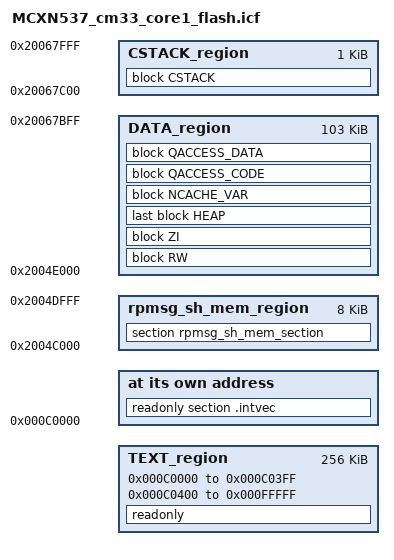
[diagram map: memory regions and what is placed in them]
/*
** ###################################################################
**     Processors:          MCXN537VAB_cm33_core1
**                          MCXN537VDF_cm33_core1
**                          MCXN537VKL_cm33_core1
**                          MCXN537VPB_cm33_core1
**
**     Compiler:            IAR ANSI C/C++ Compiler for ARM
**     Reference manual:    MCXNx4x Reference Manual
**     Version:             rev. 1.1, 2025-11-07
**     Build:               b251107
**
**     Abstract:
**         Linker file for the IAR ANSI C/C++ Compiler for ARM
**
**     Copyright 2016 Freescale Semiconductor, Inc.
**     Copyright 2016-2025 NXP
**     SPDX-License-Identifier: BSD-3-Clause
**
**     http:                 www.nxp.com
**     mail:                 support@nxp.com
**
** ###################################################################
*/


/* USB BDT size */
define symbol usb_bdt_size             = 0x200;
/* Stack and Heap Sizes */
if (isdefinedsymbol(__stack_size__)) {
  define symbol __size_cstack__        = __stack_size__;
} else {
  define symbol __size_cstack__        = 0x0400;
}

if (isdefinedsymbol(__heap_size__)) {
  define symbol __size_heap__          = __heap_size__;
} else {
  define symbol __size_heap__          = 0x0400;
}

define symbol m_interrupts_start               = 0x000C0000;
define symbol m_interrupts_end                 = 0x000C03FF;

define symbol m_text_start                     = 0x000C0400;
define symbol m_text_end                       = 0x000FFFFF;




define symbol m_data_start                     = 0x2004E000;
define symbol m_data_end                       = 0x20067FFF;

if (isdefinedsymbol(__use_shmem__)) {
  define exported symbol rpmsg_sh_mem_start      = 0x2004C000;
  define exported symbol rpmsg_sh_mem_end        = 0x2004DFFF;
}


define memory mem with size = 4G;

define region TEXT_region             = mem:[from m_interrupts_start to m_interrupts_end]
                                      | mem:[from m_text_start to m_text_end];
define region DATA_region = mem:[from m_data_start to m_data_end-__size_cstack__];
define region CSTACK_region = mem:[from m_data_end-__size_cstack__+1 to m_data_end];
if (isdefinedsymbol(__use_shmem__)) {
  define region rpmsg_sh_mem_region     = mem:[from rpmsg_sh_mem_start to rpmsg_sh_mem_end];
}

define block CSTACK        with alignment = 8, size = __size_cstack__   { };
define block HEAP          with alignment = 8, size = __size_heap__     { };
define block RW            { readwrite };
define block ZI            { zi };
define block NCACHE_VAR    { section NonCacheable , section NonCacheable.init };
define block QACCESS_CODE  { section CodeQuickAccess };
define block QACCESS_DATA  { section DataQuickAccess };



initialize by copy { readwrite, section .textrw, section CodeQuickAccess, section DataQuickAccess };

if (isdefinedsymbol(__USE_DLIB_PERTHREAD))
{
  /* Required in a multi-threaded application */
  initialize by copy with packing = none { section __DLIB_PERTHREAD };
}

do not initialize  { section .noinit, section m_usb_bdt, section m_usb_global };
if (isdefinedsymbol(__use_shmem__)) {
  do not initialize  { section rpmsg_sh_mem_section };
}

place at address mem: m_interrupts_start      { readonly section .intvec };
place in TEXT_region                          { readonly };
place in DATA_region                          { block RW };
place in DATA_region                          { block ZI };
place in DATA_region                          { last block HEAP };
place in CSTACK_region                        { block CSTACK };
place in DATA_region                          { block NCACHE_VAR };
place in DATA_region                          { block QACCESS_CODE };
place in DATA_region                          { block QACCESS_DATA };
if (isdefinedsymbol(__use_shmem__)) {
  place in rpmsg_sh_mem_region                { section rpmsg_sh_mem_section };
}

